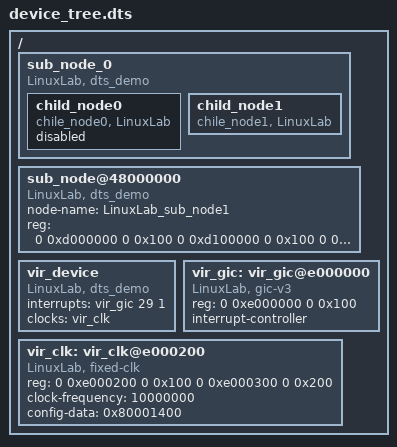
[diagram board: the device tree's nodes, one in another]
/*
 *  gpio.dts
 *  
 *  (C) 2025.01.21 <hkdywg@163.com>
 *
 *  This program is free software; you can redistribute it and/r modify
 *  it under the terms of the GNU General Public License version 2 as
 *  published by the Free Software Foundation.
 * */

/ {
    sub_node_0 {
    	compatible = "LinuxLab, dts_demo";
    	status = "okay";

		child_node0 {
			compatible = "chile_node0, LinuxLab";
			status = "disabled";
		};

		child_node1 {
			compatible = "chile_node1, LinuxLab";
			status = "okay";
		};
    };  

	sub_node@48000000 {
    	compatible = "LinuxLab, dts_demo";
    	status = "okay";
			
		node-name = "LinuxLab_sub_node1";
		reg = <0 0xd000000 0 0x100
			   0 0xd100000 0 0x100
			   0 0xd200000 0 0x100>;
	};

	vir_device {
    	compatible = "LinuxLab, dts_demo";
    	status = "okay";

		//interrupts = <&vir_gic 29 IRQ_TYPE_LEVEL_HIGH>;
		interrupts = <&vir_gic 29 1>;
		clocks = <&vir_clk>;
	};

	vir_gic: vir_gic@e000000 {
		compatible = "LinuxLab, gic-v3";
		reg = <0 0xe000000 0 0x100>;
		interrupt-controller;
		#interrupt-cells = <2>;
	};

	vir_clk: vir_clk@e000200 {
		compatible = "LinuxLab, fixed-clk";
		reg = <0 0xe000200 0 0x100
			   0 0xe000300 0 0x200>;
		clock-frequency = <10000000>;
		config-data = <0x80001400>;
		#clock-cells = <0>;
	};
};
